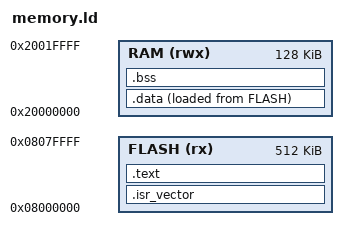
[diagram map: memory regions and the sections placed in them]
ENTRY(Reset_Handler)

/* STM32F446RE
 * Flash: 512 KB  (0x0800_0000 .. 0x0807_FFFF)
 * SRAM : 128 KB  (0x2000_0000 .. 0x2001_FFFF)
 */

MEMORY
{
  FLASH (rx)  : ORIGIN = 0x08000000, LENGTH = 512K
  RAM   (rwx) : ORIGIN = 0x20000000, LENGTH = 128K
}

/* initial stack pointer = top of SRAM */
_estack = ORIGIN(RAM) + LENGTH(RAM);

SECTIONS
{
  .isr_vector :
  {
    KEEP(*(.isr_vector))
  } > FLASH

  .text :
  {
    *(.text*)
    *(.rodata*)
    KEEP(*(.init))
    KEEP(*(.fini))
  } > FLASH

  /* .data lives in RAM but is loaded from FLASH */
  _sidata = LOADADDR(.data);
  .data :
  {
    _sdata = .;
    *(.data*)
    _edata = .;
  } > RAM AT>FLASH

  .bss :
  {
    _sbss = .;
    *(.bss*)
    *(COMMON)
    _ebss = .;
  } > RAM

  _end = .;
}
